# SP28038 register map
Vendor: NXP Semiconductors; Series: SP2083X; File version: 1.0
CPU: CM4 r0p1, little endian, no MPU, FPU, VTOR, 4 interrupt priority bits
Registers are 32-bit, read-write, reset 0x0 unless marked. A register's access mark holds for its fields unless they carry their own. Offsets are from the block's base; [hi:lo] are bit positions; {n}, {i} and the like mark numbered series.

## SDRAM — Synchronous DRAM Controller
Base 0x4000F000; register names take the prefix SDRAM_
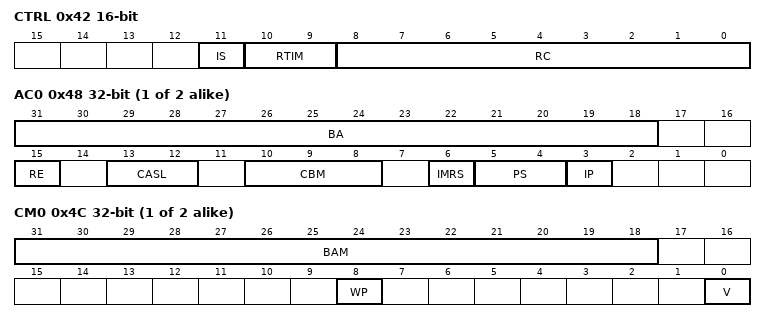
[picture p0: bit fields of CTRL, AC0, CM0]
0x42 CTRL 16-bit reset not defined — Control Register
  [11] IS — Initiate self-refresh command.
    0=Take no action or issue a selfx command to exit self refresh; 1=SDRAM controller sends a self command to both SDRAM blocks to put them in low-power, self-refresh state where they remain until IS is cleared. When IS is cleared, the controller sends a selfx command for the SDRAMs to exit self-refresh. The refresh counter is suspended while the SDRAMs are in self-refresh; the SDRAM controls the refresh period.
  [10:9] RTIM — Refresh timing
    0=3 clocks; 1=6 clocks; 2=9 clocks; 3=9 clocks
  [8:0] RC — Refresh count
{0x48+8i} AC{i} (i=0..1) (reset mask 0x8040) — Address and Control Register
  [31:18] BA — Base address register.
  [15] RE — Refresh enable
    0=Do not refresh associated DRAM block; 1=Refresh associated DRAM block
  [13:12] CASL — CAS Latency
  [10:8] CBM — Command bit location
  [6] IMRS — Initiate mode register set (mrs) command.
    0=Take no action; 1=Initiate mrs command
  [5:4] PS — Port size.
    0=32-bit port; 1=8-bit port; 2=16-bit port; 3=16-bit port
  [3] IP — Initiate precharge all (pall) command.
    0=Take no action; 1=A pall command is sent to the associated SDRAM block. During initialization, this command is executed after all DRAM controller registers are programmed. After IP is set, the next write to an appropriate SDRAM address generates the pall command to the SDRAM block.
{0x4C+8i} CM{i} (i=0..1) (reset mask 0x1) — Control Mask
  [31:18] BAM — Base address mask.
    0=The associated address bit is used in decoding the DRAM hit to a memory block; 1=The associated address bit is not used in the DRAM hit decode
  [8] WP — Write protect.
    0=Allow write accesses; 1=Ignore write accesses. The DRAM controller ignores write accesses to the memory block and an address exception occurs. Write accesses to a write-protected DRAM region are compared in the chip select module for a hit. If no hit occurs, an external bus cycle is generated. If this external bus cycle is not acknowledged, an access exception occurs.
  [0] V — Valid.
    0=Do not decode DRAM accesses; 1=Registers controlling the DRAM block are initialized; DRAM accesses can be decoded

## DMAMUX — DMA channel multiplexor
Base 0x40021000; register names take the prefix DMAMUX_
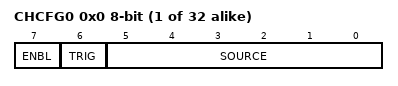
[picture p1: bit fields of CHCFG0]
{0x0+i} CHCFG{i} (i=0..31) 8-bit — Channel Configuration register
  [7] ENBL — DMA Channel Enable
    0=DMA channel is disabled. This mode is primarily used during configuration of the DMAMux. The DMA has separate channel enables/disables, which should be used to disable or reconfigure a DMA channel.; 1=DMA channel is enabled
  [6] TRIG — DMA Channel Trigger Enable
    0=Triggering is disabled. If triggering is disabled and ENBL is set, the DMA Channel will simply route the specified source to the DMA channel. (Normal mode); 1=Triggering is enabled. If triggering is enabled and ENBL is set, the DMAMUX is in Periodic Trigger mode.
  [5:0] SOURCE — DMA Channel Source (Slot)
    0=Disable_Signal; 1=TSI0_Signal; 2=UART0_Rx_Signal; 3=UART0_Tx_Signal; 4=UART1_Rx_Signal; 5=UART1_Tx_Signal; 6=UART2_Rx_Signal; 7=UART2_Tx_Signal; 8=UART3_Rx_Signal; 9=UART3_Tx_Signal; 10=UART4_Signal; 12=I2S0_Rx_Signal; 13=I2S0_Tx_Signal; 14=SPI0_Rx_Signal; 15=SPI0_Tx_Signal; 16=SPI1_Rx_Signal; 17=SPI1_Tx_Signal; 18=I2C0_I2C3_Signal; 19=I2C1_I2C2_Signal; {v}=FTM0_Channel{v-20}_Signal (v=20..27); 28=FTM1_TPM1_Channel0_Signal; 29=FTM1_TPM1_Channel1_Signal; 30=FTM2_TPM2_Channel0_Signal; 31=FTM2_TPM2_Channel1_Signal; {v}=FTM3_Channel{v-32}_Signal (v=32..37); 38=FTM3_Channel6_SPI2_Rx_Signal; 39=FTM3_Channel7_SPI2_Tx_Signal; 40=ADC0_Signal; 41=ADC1_Signal; 42=CMP0_Signal; 43=CMP1_Signal; 44=CMP2_CMP3_Signal; 45=DAC0_Signal; 46=DAC1_Signal; 47=CMT_Signal; 48=PDB_Signal; 49=PortA_Signal; 50=PortB_Signal; 51=PortC_Signal; 52=PortD_Signal; 53=PortE_Signal; 54=IEEE1588Timer0_Signal; 55=IEEE1588Timer1_TPM1_Overflow_Signal; 56=IEEE1588Timer2_TPM2_Overflow_Signal; 57=IEEE1588Timer3_Signal; 58=LPUART0_Rx_Signal; 59=LPUART0_Tx_Signal; {v}=AlwaysOn{v}_Signal (v=60..63)
